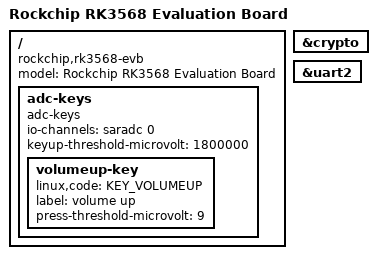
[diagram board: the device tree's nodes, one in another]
/*
 * SPDX-License-Identifier:     GPL-2.0+
 *
 * (C) Copyright 2020 Rockchip Electronics Co., Ltd
 */

/dts-v1/;
#include "rk3568.dtsi"
#include "rk3568-u-boot.dtsi"
#include <dt-bindings/input/input.h>

/ {
	model = "Rockchip RK3568 Evaluation Board";
	compatible = "rockchip,rk3568-evb", "rockchip,rk3568";

	adc-keys {
		compatible = "adc-keys";
		io-channels = <&saradc 0>;
		io-channel-names = "buttons";
		keyup-threshold-microvolt = <1800000>;
		u-boot,dm-spl;
		status = "okay";

		volumeup-key {
			u-boot,dm-spl;
			linux,code = <KEY_VOLUMEUP>;
			label = "volume up";
			press-threshold-microvolt = <9>;
		};
	};
};

&crypto {
	status = "okay";
};

&uart2 {
	status = "okay";
};
